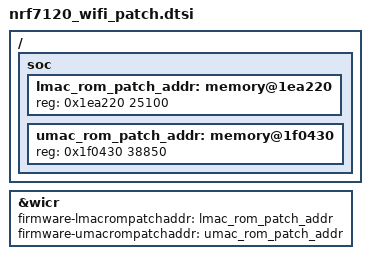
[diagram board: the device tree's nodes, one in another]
/*
 * Copyright (c) 2026 Nordic Semiconductor ASA
 *
 * SPDX-License-Identifier: LicenseRef-Nordic-5-Clause
 */

/ {
	soc {
		lmac_rom_patch_addr: memory@1ea220 {
			reg = <0x1ea220 25100>;
		};

		umac_rom_patch_addr: memory@1f0430 {
			reg = <0x1f0430 38850>;
		};
	};
};

&wicr {
	firmware-lmacrompatchaddr = <&lmac_rom_patch_addr>;
	firmware-umacrompatchaddr = <&umac_rom_patch_addr>;
};
